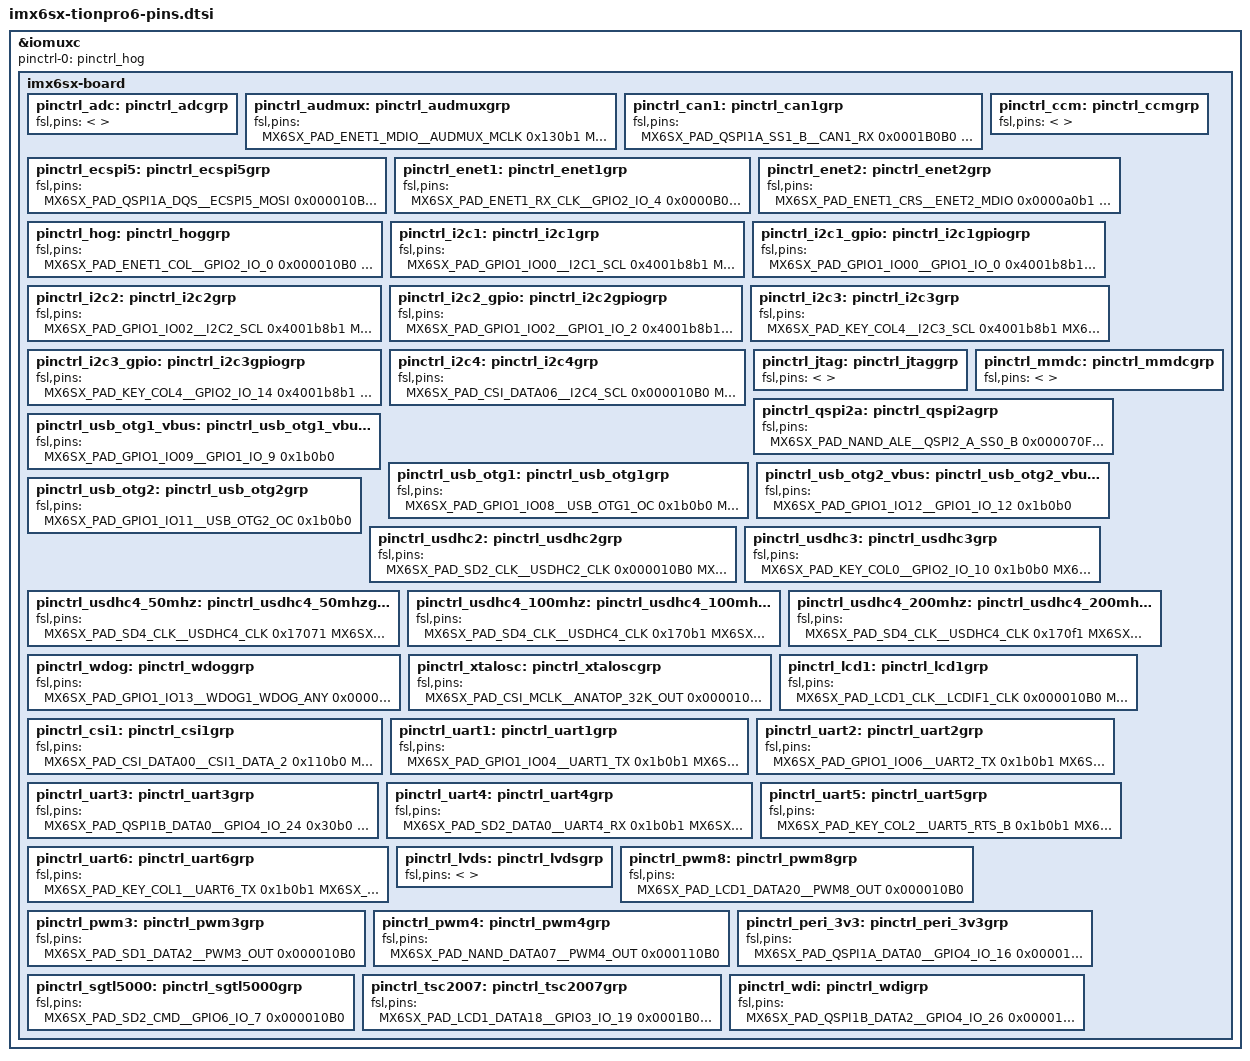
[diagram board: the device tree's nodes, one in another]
/***********************************************************************************************************************
 * This file was generated by the MCUXpresso Config Tools. Any manual edits made to this file
 * will be overwritten if the respective MCUXpresso Config Tools is used to update this file.
 **********************************************************************************************************************/


&iomuxc {
    pinctrl-names = "default";
    pinctrl-0 = <&pinctrl_hog>;

    imx6sx-board {

        pinctrl_adc: pinctrl_adcgrp {                      /*!< Function assigned for the core: Cortex-A9[ca9] */
            fsl,pins = <
            >;
        };


        pinctrl_audmux: pinctrl_audmuxgrp {                /*!< Function assigned for the core: Cortex-A9[ca9] */
            fsl,pins = <
                MX6SX_PAD_ENET1_MDIO__AUDMUX_MCLK          0x130b1
                MX6SX_PAD_SD1_DATA0__AUDMUX_AUD5_RXD       0x1b0b0
                MX6SX_PAD_SD1_DATA1__AUDMUX_AUD5_TXC       0x1b0b0
                MX6SX_PAD_SD1_DATA2__AUDMUX_AUD5_TXFS      0x1b0b0
                MX6SX_PAD_SD1_DATA3__AUDMUX_AUD5_TXD       0x1b0b0
            >;
        };


        pinctrl_can1: pinctrl_can1grp {                    /*!< Function assigned for the core: Cortex-A9[ca9] */
            fsl,pins = <
                MX6SX_PAD_QSPI1A_SS1_B__CAN1_RX            0x0001B0B0
                MX6SX_PAD_QSPI1B_DQS__CAN1_TX              0x0001B0B0
                MX6SX_PAD_QSPI1B_DATA3__GPIO4_IO_27        0x000130B0
            >;
        };


        pinctrl_ccm: pinctrl_ccmgrp {                      /*!< Function assigned for the core: Cortex-A9[ca9] */
            fsl,pins = <
            >;
        };


        pinctrl_ecspi5: pinctrl_ecspi5grp {                /*!< Function assigned for the core: Cortex-A9[ca9] */
            fsl,pins = <
                MX6SX_PAD_QSPI1A_DQS__ECSPI5_MOSI          0x000010B0
                MX6SX_PAD_QSPI1A_SS1_B__ECSPI5_MISO        0x000010B0
                MX6SX_PAD_QSPI1B_DQS__ECSPI5_SS0           0x000010B0
                MX6SX_PAD_QSPI1B_SS1_B__ECSPI5_SCLK        0x000010B0
            >;
        };


        pinctrl_enet1: pinctrl_enet1grp {                  /*!< Function assigned for the core: Cortex-A9[ca9] */
            fsl,pins = <            	       
                MX6SX_PAD_ENET1_RX_CLK__GPIO2_IO_4         0x0000B0B0
                MX6SX_PAD_ENET1_TX_CLK__GPIO2_IO_5         0x0000B0B0
                MX6SX_PAD_ENET2_CRS__GPIO2_IO_7            0x0000B0B0
                MX6SX_PAD_RGMII1_RD0__ENET1_RX_DATA_0      0x00007081
                MX6SX_PAD_RGMII1_RD1__ENET1_RX_DATA_1      0x00003081
                MX6SX_PAD_RGMII1_RD2__ENET1_RX_DATA_2      0x00007081
                MX6SX_PAD_RGMII1_RD3__ENET1_RX_DATA_3      0x00007081
                MX6SX_PAD_RGMII1_RXC__ENET1_RX_CLK         0x00007081
                MX6SX_PAD_RGMII1_RX_CTL__ENET1_RX_EN       0x00003081
                MX6SX_PAD_RGMII1_TD0__ENET1_TX_DATA_0      0x000030b1
                MX6SX_PAD_RGMII1_TD1__ENET1_TX_DATA_1      0x000030b1
                MX6SX_PAD_RGMII1_TD2__ENET1_TX_DATA_2      0x000030b1
                MX6SX_PAD_RGMII1_TD3__ENET1_TX_DATA_3      0x000030b1
                MX6SX_PAD_RGMII1_TXC__ENET1_RGMII_TXC      0x000030b1
                MX6SX_PAD_RGMII1_TX_CTL__ENET1_TX_EN       0x000030b1
            >;
        };


        pinctrl_enet2: pinctrl_enet2grp {                  /*!< Function assigned for the core: Cortex-A9[ca9] */
            fsl,pins = < 
            	MX6SX_PAD_ENET1_CRS__ENET2_MDIO            0x0000a0b1
                MX6SX_PAD_ENET1_MDC__ENET2_MDC             0x0000a0b1                                        
                MX6SX_PAD_ENET2_COL__GPIO2_IO_6            0x0000B0B0
                MX6SX_PAD_ENET2_RX_CLK__GPIO2_IO_8         0x0000B0B0
                MX6SX_PAD_ENET2_TX_CLK__GPIO2_IO_9         0x0000B0B0
                MX6SX_PAD_RGMII2_RD0__ENET2_RX_DATA_0      0x00003081
                MX6SX_PAD_RGMII2_RD1__ENET2_RX_DATA_1      0x00003081
                MX6SX_PAD_RGMII2_RD2__ENET2_RX_DATA_2      0x00007081
                MX6SX_PAD_RGMII2_RD3__ENET2_RX_DATA_3      0x00007081
                MX6SX_PAD_RGMII2_RXC__ENET2_RX_CLK         0x00007081
                MX6SX_PAD_RGMII2_RX_CTL__ENET2_RX_EN       0x00003081
                MX6SX_PAD_RGMII2_TD0__ENET2_TX_DATA_0      0x0000a0b1
                MX6SX_PAD_RGMII2_TD1__ENET2_TX_DATA_1      0x0000a0b1
                MX6SX_PAD_RGMII2_TD2__ENET2_TX_DATA_2      0x0000a0b1
                MX6SX_PAD_RGMII2_TD3__ENET2_TX_DATA_3      0x0000a0b1
                MX6SX_PAD_RGMII2_TXC__ENET2_RGMII_TXC      0x0000a0B1
                MX6SX_PAD_RGMII2_TX_CTL__ENET2_TX_EN       0x0000a0b1
            >;
        };


        pinctrl_hog: pinctrl_hoggrp {                      /*!< Function assigned for the core: Cortex-A9[ca9] */
            fsl,pins = <
                //MX6SX_PAD_CSI_DATA02__GPIO1_IO_16          0x000010B0
                //MX6SX_PAD_CSI_DATA03__GPIO1_IO_17          0x000010B0
                //MX6SX_PAD_CSI_DATA04__GPIO1_IO_18          0x000010B0
                //MX6SX_PAD_CSI_DATA05__GPIO1_IO_19          0x000010B0
                MX6SX_PAD_ENET1_COL__GPIO2_IO_0            0x000010B0
                MX6SX_PAD_LCD1_DATA19__GPIO3_IO_20         0x000010B0
                //MX6SX_PAD_LCD1_DATA20__GPIO3_IO_21         0x000010B0
                MX6SX_PAD_LCD1_DATA21__GPIO3_IO_22         0x000010B0
                MX6SX_PAD_LCD1_DATA22__GPIO3_IO_23         0x000010B0
                MX6SX_PAD_LCD1_DATA23__GPIO3_IO_24         0x000010B0
                //MX6SX_PAD_LCD1_ENABLE__GPIO3_IO_25         0x000010B0
                //MX6SX_PAD_LCD1_HSYNC__GPIO3_IO_26          0x000010B0
                //MX6SX_PAD_LCD1_RESET__GPIO3_IO_27          0x000010B0
                //MX6SX_PAD_LCD1_VSYNC__GPIO3_IO_28          0x000010B0
                //MX6SX_PAD_NAND_ALE__GPIO4_IO_0             0x000010B0
                //MX6SX_PAD_NAND_CE0_B__GPIO4_IO_1           0x000010B0
                //MX6SX_PAD_NAND_CE1_B__GPIO4_IO_2           0x000010B0
                //MX6SX_PAD_NAND_CLE__GPIO4_IO_3             0x000010B0
                MX6SX_PAD_NAND_DATA00__GPIO4_IO_4          0x000010B0
                MX6SX_PAD_NAND_DATA01__GPIO4_IO_5          0x000010B0
                MX6SX_PAD_NAND_DATA02__GPIO4_IO_6          0x000010B0
                MX6SX_PAD_NAND_DATA03__GPIO4_IO_7          0x000010B0
                MX6SX_PAD_NAND_DATA04__GPIO4_IO_8          0x000010B0
                MX6SX_PAD_NAND_DATA05__GPIO4_IO_9          0x000010B0
                MX6SX_PAD_NAND_DATA06__GPIO4_IO_10         0x000010B0
                //MX6SX_PAD_NAND_DATA07__GPIO4_IO_11         0x000010B0
                //MX6SX_PAD_NAND_READY_B__GPIO4_IO_13        0x000010B0
                MX6SX_PAD_NAND_RE_B__GPIO4_IO_12           0x000010B0
                MX6SX_PAD_NAND_WE_B__GPIO4_IO_14           0x000010B0
                //MX6SX_PAD_NAND_WP_B__GPIO4_IO_15           0x000010B0
                MX6SX_PAD_QSPI1A_DATA1__GPIO4_IO_17        0x000010B0
                MX6SX_PAD_QSPI1A_DATA2__GPIO4_IO_18        0x000010B0
                MX6SX_PAD_QSPI1A_DATA3__GPIO4_IO_19        0x000010B0
                MX6SX_PAD_QSPI1A_SCLK__GPIO4_IO_21         0x000010B0
                MX6SX_PAD_QSPI1A_SS0_B__GPIO4_IO_22        0x000010B0
                //MX6SX_PAD_QSPI1B_DATA0__GPIO4_IO_24        0x000010B0
                //MX6SX_PAD_QSPI1B_DATA1__GPIO4_IO_25        0x000010B0
                //MX6SX_PAD_QSPI1B_DATA2__GPIO4_IO_26        0x000010B0
                //MX6SX_PAD_QSPI1B_DATA3__GPIO4_IO_27        0x000010B0
                MX6SX_PAD_SD1_CLK__GPIO6_IO_0              0x000010B0
                MX6SX_PAD_SD1_CMD__GPIO6_IO_1              0x000010B0
                //MX6SX_PAD_GPIO1_IO13__WDOG1_WDOG_ANY       0x000010B0
            >;
        };


        pinctrl_i2c1: pinctrl_i2c1grp {                    /*!< Function assigned for the core: Cortex-A9[ca9] */
            fsl,pins = <
                MX6SX_PAD_GPIO1_IO00__I2C1_SCL             0x4001b8b1
                MX6SX_PAD_GPIO1_IO01__I2C1_SDA             0x4001b8b1
            >;
        };
        
        pinctrl_i2c1_gpio: pinctrl_i2c1gpiogrp {                    /*!< Function assigned for the core: Cortex-A9[ca9] */
            fsl,pins = <
                MX6SX_PAD_GPIO1_IO00__GPIO1_IO_0              0x4001b8b1
                MX6SX_PAD_GPIO1_IO01__GPIO1_IO_1              0x4001b8b1
            >;
        };


        pinctrl_i2c2: pinctrl_i2c2grp {                    /*!< Function assigned for the core: Cortex-A9[ca9] */
            fsl,pins = <
                MX6SX_PAD_GPIO1_IO02__I2C2_SCL             0x4001b8b1
                MX6SX_PAD_GPIO1_IO03__I2C2_SDA             0x4001b8b1
            >;
        };
        
        pinctrl_i2c2_gpio: pinctrl_i2c2gpiogrp {                    /*!< Function assigned for the core: Cortex-A9[ca9] */
            fsl,pins = <
                MX6SX_PAD_GPIO1_IO02__GPIO1_IO_2             0x4001b8b1
                MX6SX_PAD_GPIO1_IO03__GPIO1_IO_3             0x4001b8b1
            >;
        };


        pinctrl_i2c3: pinctrl_i2c3grp {                    /*!< Function assigned for the core: Cortex-A9[ca9] */
            fsl,pins = <
                MX6SX_PAD_KEY_COL4__I2C3_SCL               0x4001b8b1
                MX6SX_PAD_KEY_ROW4__I2C3_SDA               0x4001b8b1
            >;
        };
        
        pinctrl_i2c3_gpio: pinctrl_i2c3gpiogrp {                    /*!< Function assigned for the core: Cortex-A9[ca9] */
            fsl,pins = <
                MX6SX_PAD_KEY_COL4__GPIO2_IO_14               0x4001b8b1
                MX6SX_PAD_KEY_ROW4__GPIO2_IO_19               0x4001b8b1
            >;
        };


        pinctrl_i2c4: pinctrl_i2c4grp {                    /*!< Function assigned for the core: Cortex-A9[ca9] */
            fsl,pins = <
                MX6SX_PAD_CSI_DATA06__I2C4_SCL             0x000010B0
                MX6SX_PAD_CSI_DATA07__I2C4_SDA             0x000010B0
            >;
        };


        pinctrl_jtag: pinctrl_jtaggrp {                    /*!< Function assigned for the core: Cortex-A9[ca9] */
            fsl,pins = <
            >;
        };


        pinctrl_mmdc: pinctrl_mmdcgrp {                    /*!< Function assigned for the core: Cortex-A9[ca9] */
            fsl,pins = <
            >;
        };


       pinctrl_qspi2a: pinctrl_qspi2agrp {                /*!< Function assigned for the core: Cortex-A9[ca9] */
            fsl,pins = <
                MX6SX_PAD_NAND_ALE__QSPI2_A_SS0_B          0x000070F1
                MX6SX_PAD_NAND_CE0_B__QSPI2_A_DATA_2       0x000070F1
                MX6SX_PAD_NAND_CE1_B__QSPI2_A_DATA_3       0x000070F1
                MX6SX_PAD_NAND_CLE__QSPI2_A_SCLK           0x000070F1
                MX6SX_PAD_NAND_READY_B__QSPI2_A_DATA_1     0x000070F1
                MX6SX_PAD_NAND_WP_B__QSPI2_A_DATA_0        0x000070F1
            >;
        };


         pinctrl_usb_otg1_vbus: pinctrl_usb_otg1_vbusgrp {  /*!< Function assigned for the core: Cortex-A9[ca9] */
            fsl,pins = <
                MX6SX_PAD_GPIO1_IO09__GPIO1_IO_9         0x1b0b0
            >;
        };
        
        pinctrl_usb_otg1: pinctrl_usb_otg1grp {            /*!< Function assigned for the core: Cortex-A9[ca9] */
            fsl,pins = <
                MX6SX_PAD_GPIO1_IO08__USB_OTG1_OC          0x1b0b0
                MX6SX_PAD_GPIO1_IO10__ANATOP_OTG1_ID       0x170b1
            >;
        };        
       


        pinctrl_usb_otg2_vbus: pinctrl_usb_otg2_vbusgrp {  /*!< Function assigned for the core: Cortex-A9[ca9] */
            fsl,pins = <
                MX6SX_PAD_GPIO1_IO12__GPIO1_IO_12         0x1b0b0
            >;
        };
        


        pinctrl_usb_otg2: pinctrl_usb_otg2grp {            /*!< Function assigned for the core: Cortex-A9[ca9] */
            fsl,pins = <
                MX6SX_PAD_GPIO1_IO11__USB_OTG2_OC          0x1b0b0
            >;
        };


        pinctrl_usdhc2: pinctrl_usdhc2grp {                /*!< Function assigned for the core: Cortex-A9[ca9] */
            fsl,pins = <
                MX6SX_PAD_SD2_CLK__USDHC2_CLK              0x000010B0
                MX6SX_PAD_SD2_CMD__USDHC2_CMD              0x000010B0
                MX6SX_PAD_SD2_DATA0__USDHC2_DATA0          0x000010B0
                MX6SX_PAD_SD2_DATA1__USDHC2_DATA1          0x000010B0
                MX6SX_PAD_SD2_DATA2__USDHC2_DATA2          0x000010B0
                MX6SX_PAD_SD2_DATA3__USDHC2_DATA3          0x000010B0
            >;
        };


        pinctrl_usdhc3: pinctrl_usdhc3grp {                /*!< Function assigned for the core: Cortex-A9[ca9] */
            fsl,pins = <
                //MX6SX_PAD_KEY_COL0__USDHC3_CD_B            0x000010B0
                MX6SX_PAD_KEY_COL0__GPIO2_IO_10		0x1b0b0
                MX6SX_PAD_SD3_CLK__USDHC3_CLK              0x10071
                MX6SX_PAD_SD3_CMD__USDHC3_CMD              0x1f071
                MX6SX_PAD_SD3_DATA0__USDHC3_DATA0          0x1f071
                MX6SX_PAD_SD3_DATA1__USDHC3_DATA1          0x1f071
                MX6SX_PAD_SD3_DATA2__USDHC3_DATA2          0x1f071
                MX6SX_PAD_SD3_DATA3__USDHC3_DATA3          0x1f071
            >;
        };
        
        pinctrl_usdhc4_50mhz: pinctrl_usdhc4_50mhzgrp {                /*!< Function assigned for the core: Cortex-A9[ca9] */
            fsl,pins = <
                MX6SX_PAD_SD4_CLK__USDHC4_CLK              0x17071
                MX6SX_PAD_SD4_CMD__USDHC4_CMD              0x17071
                MX6SX_PAD_SD4_DATA0__USDHC4_DATA0          0x17071
                MX6SX_PAD_SD4_DATA1__USDHC4_DATA1          0x17071
                MX6SX_PAD_SD4_DATA2__USDHC4_DATA2          0x17071
                MX6SX_PAD_SD4_DATA3__USDHC4_DATA3          0x17071
                MX6SX_PAD_SD4_DATA4__USDHC4_DATA4          0x17071
                MX6SX_PAD_SD4_DATA5__USDHC4_DATA5          0x17071
                MX6SX_PAD_SD4_DATA6__USDHC4_DATA6          0x17071
                MX6SX_PAD_SD4_DATA7__USDHC4_DATA7          0x17071
                MX6SX_PAD_SD4_RESET_B__USDHC4_RESET_B      0x17071
            >;
        };
        
         pinctrl_usdhc4_100mhz: pinctrl_usdhc4_100mhzgrp {                /*!< Function assigned for the core: Cortex-A9[ca9] */
            fsl,pins = <
                MX6SX_PAD_SD4_CLK__USDHC4_CLK              0x170b1
                MX6SX_PAD_SD4_CMD__USDHC4_CMD              0x170b1
                MX6SX_PAD_SD4_DATA0__USDHC4_DATA0          0x170b1
                MX6SX_PAD_SD4_DATA1__USDHC4_DATA1          0x170b1
                MX6SX_PAD_SD4_DATA2__USDHC4_DATA2          0x170b1
                MX6SX_PAD_SD4_DATA3__USDHC4_DATA3          0x170b1
                MX6SX_PAD_SD4_DATA4__USDHC4_DATA4          0x170b1
                MX6SX_PAD_SD4_DATA5__USDHC4_DATA5          0x170b1
                MX6SX_PAD_SD4_DATA6__USDHC4_DATA6          0x170b1
                MX6SX_PAD_SD4_DATA7__USDHC4_DATA7          0x170b1
                MX6SX_PAD_SD4_RESET_B__USDHC4_RESET_B      0x170b1
            >;
        };
        
         pinctrl_usdhc4_200mhz: pinctrl_usdhc4_200mhzgrp {                /*!< Function assigned for the core: Cortex-A9[ca9] */
            fsl,pins = <
                MX6SX_PAD_SD4_CLK__USDHC4_CLK              0x170f1
                MX6SX_PAD_SD4_CMD__USDHC4_CMD              0x170f1
                MX6SX_PAD_SD4_DATA0__USDHC4_DATA0          0x170f1
                MX6SX_PAD_SD4_DATA1__USDHC4_DATA1          0x170f1
                MX6SX_PAD_SD4_DATA2__USDHC4_DATA2          0x170f1
                MX6SX_PAD_SD4_DATA3__USDHC4_DATA3          0x170f1
                MX6SX_PAD_SD4_DATA4__USDHC4_DATA4          0x170f1
                MX6SX_PAD_SD4_DATA5__USDHC4_DATA5          0x170f1
                MX6SX_PAD_SD4_DATA6__USDHC4_DATA6          0x170f1
                MX6SX_PAD_SD4_DATA7__USDHC4_DATA7          0x170f1
                MX6SX_PAD_SD4_RESET_B__USDHC4_RESET_B      0x170f1
            >;
        };


        pinctrl_wdog: pinctrl_wdoggrp {                    /*!< Function assigned for the core: Cortex-A9[ca9] */
            fsl,pins = <
                MX6SX_PAD_GPIO1_IO13__WDOG1_WDOG_ANY       0x000010B0
            >;
        };


        pinctrl_xtalosc: pinctrl_xtaloscgrp {              /*!< Function assigned for the core: Cortex-A9[ca9] */
            fsl,pins = <
                MX6SX_PAD_CSI_MCLK__ANATOP_32K_OUT         0x000010B0
            >;
        };


        pinctrl_lcd1: pinctrl_lcd1grp {                    /*!< Function assigned for the core: Cortex-A9[ca9] */
            fsl,pins = <
                MX6SX_PAD_LCD1_CLK__LCDIF1_CLK             0x000010B0
                MX6SX_PAD_LCD1_DATA00__LCDIF1_DATA_0       0x000010B0
                MX6SX_PAD_LCD1_DATA01__LCDIF1_DATA_1       0x000010B0
                MX6SX_PAD_LCD1_DATA02__LCDIF1_DATA_2       0x000010B0
                MX6SX_PAD_LCD1_DATA03__LCDIF1_DATA_3       0x000010B0
                MX6SX_PAD_LCD1_DATA04__LCDIF1_DATA_4       0x000010B0
                MX6SX_PAD_LCD1_DATA05__LCDIF1_DATA_5       0x000010B0
                MX6SX_PAD_LCD1_DATA06__LCDIF1_DATA_6       0x000010B0
                MX6SX_PAD_LCD1_DATA07__LCDIF1_DATA_7       0x000010B0
                MX6SX_PAD_LCD1_DATA08__LCDIF1_DATA_8       0x000010B0
                MX6SX_PAD_LCD1_DATA09__LCDIF1_DATA_9       0x000010B0
                MX6SX_PAD_LCD1_DATA10__LCDIF1_DATA_10      0x000010B0
                MX6SX_PAD_LCD1_DATA11__LCDIF1_DATA_11      0x000010B0
                MX6SX_PAD_LCD1_DATA12__LCDIF1_DATA_12      0x000010B0
                MX6SX_PAD_LCD1_DATA13__LCDIF1_DATA_13      0x000010B0
                MX6SX_PAD_LCD1_DATA14__LCDIF1_DATA_14      0x000010B0
                MX6SX_PAD_LCD1_DATA15__LCDIF1_DATA_15      0x000010B0
                MX6SX_PAD_LCD1_DATA16__LCDIF1_DATA_16      0x000010B0
                MX6SX_PAD_LCD1_DATA17__LCDIF1_DATA_17      0x000010B0
                MX6SX_PAD_LCD1_ENABLE__LCDIF1_ENABLE       0x000010B0
                MX6SX_PAD_LCD1_HSYNC__LCDIF1_HSYNC         0x000010B0                
                MX6SX_PAD_LCD1_RESET__GPIO3_IO_27          0x000030B0
                MX6SX_PAD_LCD1_VSYNC__LCDIF1_VSYNC         0x000010B0
            >;
        };


        pinctrl_csi1: pinctrl_csi1grp {                    /*!< Function assigned for the core: Cortex-A9[ca9] */
            fsl,pins = <
                MX6SX_PAD_CSI_DATA00__CSI1_DATA_2          0x110b0
                MX6SX_PAD_CSI_DATA01__CSI1_DATA_3          0x110b0
                MX6SX_PAD_CSI_DATA02__CSI1_DATA_4          0x110b0
                MX6SX_PAD_CSI_DATA03__CSI1_DATA_5          0x110b0
                MX6SX_PAD_CSI_DATA04__CSI1_DATA_6          0x110b0
                MX6SX_PAD_CSI_DATA05__CSI1_DATA_7          0x110b0
                MX6SX_PAD_CSI_DATA06__CSI1_DATA_8          0x110b0
                MX6SX_PAD_CSI_DATA07__CSI1_DATA_9          0x110b0
                MX6SX_PAD_CSI_HSYNC__CSI1_HSYNC           0x110b0
                MX6SX_PAD_CSI_MCLK__CSI1_MCLK               0x110b0
                MX6SX_PAD_CSI_PIXCLK__CSI1_PIXCLK           0xb0b1
                MX6SX_PAD_CSI_VSYNC__CSI1_VSYNC            0x110b0
            >;
        };


        pinctrl_uart1: pinctrl_uart1grp {                  /*!< Function assigned for the core: Cortex-A9[ca9] */
            fsl,pins = <
                MX6SX_PAD_GPIO1_IO04__UART1_TX             0x1b0b1
                MX6SX_PAD_GPIO1_IO05__UART1_RX             0x1b0b1
            >;
        };


        pinctrl_uart2: pinctrl_uart2grp {                  /*!< Function assigned for the core: Cortex-A9[ca9] */
            fsl,pins = <
                MX6SX_PAD_GPIO1_IO06__UART2_TX             0x1b0b1
                MX6SX_PAD_GPIO1_IO07__UART2_RX             0x1b0b1
            >;
        };


        pinctrl_uart3: pinctrl_uart3grp {                  /*!< Function assigned for the core: Cortex-A9[ca9] */
            fsl,pins = <
                //MX6SX_PAD_QSPI1B_DATA0__UART3_CTS_B        0x1b0b1
                MX6SX_PAD_QSPI1B_DATA0__GPIO4_IO_24        0x30b0
                MX6SX_PAD_QSPI1B_SCLK__UART3_RX            0x1b0b1
                MX6SX_PAD_QSPI1B_SS0_B__UART3_TX           0x1b0b1
            >;
        };


        pinctrl_uart4: pinctrl_uart4grp {                  /*!< Function assigned for the core: Cortex-A9[ca9] */
            fsl,pins = <
                MX6SX_PAD_SD2_DATA0__UART4_RX              0x1b0b1
                MX6SX_PAD_SD2_DATA1__UART4_TX              0x1b0b1
            >;
        };


        pinctrl_uart5: pinctrl_uart5grp {                  /*!< Function assigned for the core: Cortex-A9[ca9] */
            fsl,pins = <
                MX6SX_PAD_KEY_COL2__UART5_RTS_B            0x1b0b1
                MX6SX_PAD_KEY_COL3__UART5_TX               0x1b0b1
                MX6SX_PAD_KEY_ROW2__UART5_CTS_B            0x1b0b1
                MX6SX_PAD_KEY_ROW3__UART5_RX               0x1b0b1
            >;
        };


        pinctrl_uart6: pinctrl_uart6grp {                  /*!< Function assigned for the core: Cortex-A9[ca9] */
            fsl,pins = <
                MX6SX_PAD_KEY_COL1__UART6_TX               0x1b0b1
                MX6SX_PAD_KEY_ROW1__UART6_RX               0x1b0b1
                MX6SX_PAD_KEY_ROW0__UART6_CTS_B           0x1b0b1
                //MX6SX_PAD_KEY_ROW0__GPIO2_IO_15        0x30b0                
                //MX6SX_PAD_CSI_DATA06__UART6_RTS_B	0x1b0b1
               // MX6SX_PAD_KEY_COL1__UART6_RX               0x1b0b1
                //MX6SX_PAD_KEY_ROW0__UART6_RTS_B           0x1b0b1
                //MX6SX_PAD_KEY_ROW1__UART6_TX               0x1b0b1
            >;
        };


        pinctrl_lvds: pinctrl_lvdsgrp {                    /*!< Function assigned for the core: Cortex-A9[ca9] */
            fsl,pins = <
            >;
        };


        pinctrl_pwm8: pinctrl_pwm8grp {                    /*!< Function assigned for the core: Cortex-A9[ca9] */
            fsl,pins = <
                MX6SX_PAD_LCD1_DATA20__PWM8_OUT            0x000010B0
            >;
        };


        pinctrl_pwm3: pinctrl_pwm3grp {                    /*!< Function assigned for the core: Cortex-A9[ca9] */
            fsl,pins = <
                MX6SX_PAD_SD1_DATA2__PWM3_OUT              0x000010B0
            >;
        };


        pinctrl_pwm4: pinctrl_pwm4grp {                    /*!< Function assigned for the core: Cortex-A9[ca9] */
            fsl,pins = <
                MX6SX_PAD_NAND_DATA07__PWM4_OUT            0x000110B0
            >;
        };


        pinctrl_peri_3v3: pinctrl_peri_3v3grp {            /*!< Function assigned for the core: Cortex-A9[ca9] */
            fsl,pins = <
                MX6SX_PAD_QSPI1A_DATA0__GPIO4_IO_16        0x00001030
            >;
        };
        
        
        pinctrl_sgtl5000: pinctrl_sgtl5000grp {            /*!< Function assigned for the core: Cortex-A9[ca9] */
            fsl,pins = <
                MX6SX_PAD_SD2_CMD__GPIO6_IO_7              0x000010B0
            >;
        };
        
        pinctrl_tsc2007: pinctrl_tsc2007grp {              /*!< Function assigned for the core: Cortex-A9[ca9] */
            fsl,pins = <
                MX6SX_PAD_LCD1_DATA18__GPIO3_IO_19         0x0001B0B0
            >;
        };
        
        pinctrl_wdi: pinctrl_wdigrp {                      /*!< Function assigned for the core: Cortex-A9[ca9] */
            fsl,pins = <
                MX6SX_PAD_QSPI1B_DATA2__GPIO4_IO_26        0x000010B0
                MX6SX_PAD_QSPI1B_DATA1__GPIO4_IO_25        0x000010B0
            >;
        };

    };
};


